AUTOSAR XML (schema 4-3-0)
package /ComponentTypes
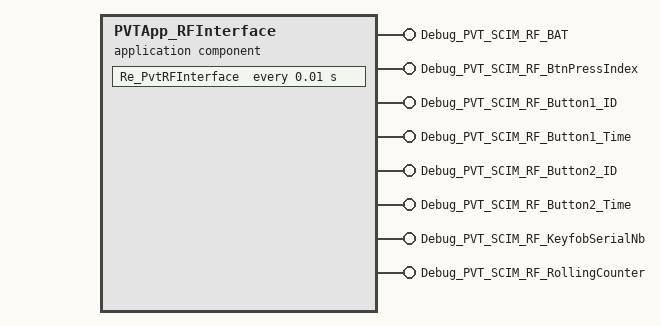
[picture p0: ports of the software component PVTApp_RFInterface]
  application sw component type PVTApp_RFInterface
    8 x provide port:
      Debug_PVT_SCIM_RF_BAT: nonqueued-sender-com-spec{data-element=Debug_PVT_SCIM_RF_BAT, init-value=0}, provided-interface=Debug_PVT_SCIM_RF_BAT
      Debug_PVT_SCIM_RF_BtnPressIndex: nonqueued-sender-com-spec{data-element=Debug_PVT_SCIM_RF_BtnPressIndex, init-value=0}, provided-interface=Debug_PVT_SCIM_RF_BtnPressIndex
      Debug_PVT_SCIM_RF_Button1_ID: nonqueued-sender-com-spec{data-element=Debug_PVT_SCIM_RF_Button1_ID, init-value=0}, provided-interface=Debug_PVT_SCIM_RF_Button1_ID
      Debug_PVT_SCIM_RF_Button1_Time: nonqueued-sender-com-spec{data-element=Debug_PVT_SCIM_RF_Button1_Time, init-value=0}, provided-interface=Debug_PVT_SCIM_RF_Button1_Time
      Debug_PVT_SCIM_RF_Button2_ID: nonqueued-sender-com-spec{data-element=Debug_PVT_SCIM_RF_Button2_ID, init-value=0}, provided-interface=Debug_PVT_SCIM_RF_Button2_ID
      Debug_PVT_SCIM_RF_Button2_Time: nonqueued-sender-com-spec{data-element=Debug_PVT_SCIM_RF_Button2_Time, init-value=0}, provided-interface=Debug_PVT_SCIM_RF_Button2_Time
      Debug_PVT_SCIM_RF_KeyfobSerialNb: nonqueued-sender-com-spec{data-element=Debug_PVT_SCIM_RF_KeyfobSerialNb, init-value=0}, provided-interface=Debug_PVT_SCIM_RF_KeyfobSerialNb
      Debug_PVT_SCIM_RF_RollingCounter: nonqueued-sender-com-spec{data-element=Debug_PVT_SCIM_RF_RollingCounter, init-value=0}, provided-interface=Debug_PVT_SCIM_RF_RollingCounter
    behavior PVTApp_RFInterface_InternalBehavior
      timing event TMT_Re_PvtRFInterface: start-on-event=Re_PvtRFInterface, period=0.01
      runnable Re_PvtRFInterface
        data-send-points:
          8 x access:
            SEND_Debug_PVT_SCIM_RF_BAT_Debug_PVT_SCIM_RF_BAT: accessed-variable=Debug_PVT_SCIM_RF_BAT.Debug_PVT_SCIM_RF_BAT
            SEND_Debug_PVT_SCIM_RF_BtnPressIndex_Debug_PVT_SCIM_RF_BtnPressIndex: accessed-variable=Debug_PVT_SCIM_RF_BtnPressIndex.Debug_PVT_SCIM_RF_BtnPressIndex
            SEND_Debug_PVT_SCIM_RF_Button1_ID_Debug_PVT_SCIM_RF_Button1_ID: accessed-variable=Debug_PVT_SCIM_RF_Button1_ID.Debug_PVT_SCIM_RF_Button1_ID
            SEND_Debug_PVT_SCIM_RF_Button1_Time_Debug_PVT_SCIM_RF_Button1_Time: accessed-variable=Debug_PVT_SCIM_RF_Button1_Time.Debug_PVT_SCIM_RF_Button1_Time
            SEND_Debug_PVT_SCIM_RF_Button2_ID_Debug_PVT_SCIM_RF_Button2_ID: accessed-variable=Debug_PVT_SCIM_RF_Button2_ID.Debug_PVT_SCIM_RF_Button2_ID
            SEND_Debug_PVT_SCIM_RF_Button2_Time_Debug_PVT_SCIM_RF_Button2_Time: accessed-variable=Debug_PVT_SCIM_RF_Button2_Time.Debug_PVT_SCIM_RF_Button2_Time
            SEND_Debug_PVT_SCIM_RF_KeyfobSerialNb_Debug_PVT_SCIM_RF_KeyfobSerialNb: accessed-variable=Debug_PVT_SCIM_RF_KeyfobSerialNb.Debug_PVT_SCIM_RF_KeyfobSerialNb
            SEND_Debug_PVT_SCIM_RF_RollingCounter_Debug_PVT_SCIM_RF_RollingCounter: accessed-variable=Debug_PVT_SCIM_RF_RollingCounter.Debug_PVT_SCIM_RF_RollingCounter
  swc implementation PVTApp_RFInterface_Implementation: behavior=PVTApp_RFInterface_InternalBehavior
    code-descriptors:
      code Default: artifact-descriptors=autosar-engineering-object=category=SWSRC
